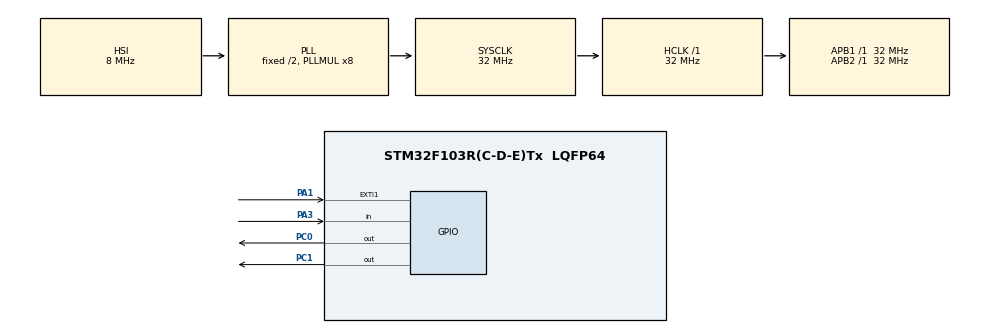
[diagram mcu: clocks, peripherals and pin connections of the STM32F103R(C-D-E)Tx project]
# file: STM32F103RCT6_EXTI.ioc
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Mcu.Family=STM32F1
PA3.GPIO_PuPd=GPIO_PULLUP
NVIC.TIM1_UP_IRQn=true\:0\:0\:false\:false\:true\:true\:true
PC0.Signal=GPIO_Output
RCC.SYSCLKSource=RCC_SYSCLKSOURCE_PLLCLK
ProjectManager.StackSize=0x400
PA13.Signal=SYS_JTMS-SWDIO
NVIC.EXTI1_IRQn=true\:0\:0\:false\:false\:true\:true\:true
TIM1.Prescaler=9
ProjectManager.TargetToolchain=STM32CubeIDE
RCC.HCLKFreq_Value=32000000
RCC.APB2TimFreq_Value=32000000
RCC.USBFreq_Value=32000000
PA1.GPIO_PuPd=GPIO_PULLUP
PA1.Signal=GPXTI1
RCC.AHBFreq_Value=32000000
board=custom
RCC.PLLMUL=RCC_PLL_MUL8
RCC.APB2Freq_Value=32000000
PA14.Mode=Serial_Wire
PA13.Mode=Serial_Wire
Mcu.Name=STM32F103R(C-D-E)Tx
VP_TIM1_VS_ClockSourceINT.Mode=Internal
RCC.SYSCLKFreq_VALUE=32000000
Mcu.Package=LQFP64
PA14.Signal=SYS_JTCK-SWCLK
ProjectManager.HeapSize=0x200
NVIC.PriorityGroup=NVIC_PRIORITYGROUP_4
RCC.APB1TimFreq_Value=32000000
TIM1.Period=319
RCC.APB1Freq_Value=32000000
PA1.GPIO_ModeDefaultEXTI=GPIO_MODE_IT_RISING_FALLING
PC1.Signal=GPIO_Output
PA3.Signal=GPIO_Input

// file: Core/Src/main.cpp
/* USER CODE BEGIN Header */
/**
  ******************************************************************************
  * @file           : main.c
  * @brief          : Main program body
  ******************************************************************************
  * @attention
  *
  * <h2><center>&copy; Copyright (c) 2021 STMicroelectronics.
  * All rights reserved.</center></h2>
  *
  * This software component is licensed by ST under BSD 3-Clause license,
  * the "License"; You may not use this file except in compliance with the
  * License. You may obtain a copy of the License at:
  *                        opensource.org/licenses/BSD-3-Clause
  *
  ******************************************************************************
  */
/* USER CODE END Header */
#include "main.h"
#include <STM32Flash.h>
#include <RCSwitch.h>
#include "stm32f1xx_hal.h"

#define DATA_START_ADDRESS	((uint32_t)0x0801FC00)

TIM_HandleTypeDef htim1;
void SystemClock_Config(void);
static void MX_GPIO_Init(void);
static void MX_TIM1_Init(void);

RCSwitch mySwitch = RCSwitch();
STM32Flash flash;
/***********************************************************/
void UpdateRemoteCode(void)
{
	uint32_t temp=0, varNew = 0;
	uint32_t buff[4];
	for(uint8_t i=0; i<4; i++)
	{
		temp = i;
		while(!mySwitch.available());
		varNew = (uint32_t)mySwitch.getReceivedValue();
		if(i==0)
		{
			buff[i] = varNew;
		}
		else
		{
			if(buff[i-1] != varNew)
			{
				buff[i] = varNew;
			}
			else
			{
				i= temp -1;
			}
		}
		mySwitch.resetAvailable();
	}
	flash.flashErase(DATA_START_ADDRESS);
	for(uint8_t i=0; i<4; i++)
	{
		HAL_FLASH_Program(FLASH_TYPEPROGRAM_WORD, DATA_START_ADDRESS+ i*4, buff[i]);
	}
}
/***********************************************************/
uint8_t GetPosition(uint32_t data)
{
	for(uint32_t i=0; i<4; i++)
	{
		if( (*(uint32_t*)(DATA_START_ADDRESS + i*4)) == data)
		{
			return i;
		}
	}
	return 4;
}
/***********************************************************/
int main(void)
{

	uint32_t blink_count = 0;
	HAL_Init();
	SystemClock_Config();
	MX_GPIO_Init();
	MX_TIM1_Init();
	HAL_TIM_Base_Start_IT(&htim1);
	mySwitch.enableReceive(0);
	Utility().delayInit();
	if(HAL_GPIO_ReadPin(GPIOA, GPIO_PIN_3)== GPIO_PIN_RESET)
	{
		UpdateRemoteCode();
	}
	while (1)
	{
		if (mySwitch.available())
		{
			switch (GetPosition((uint32_t)mySwitch.getReceivedValue()))
			{
			case 0:
				HAL_GPIO_WritePin(GPIOC, GPIO_PIN_0, GPIO_PIN_SET);
				break;
			case 1:
				HAL_GPIO_WritePin(GPIOC, GPIO_PIN_0, GPIO_PIN_RESET);
				break;
			case 2:
				HAL_GPIO_WritePin(GPIOC, GPIO_PIN_1, GPIO_PIN_SET);
				break;
			case 3:
				HAL_GPIO_WritePin(GPIOC, GPIO_PIN_1, GPIO_PIN_RESET);
				break;
			}
			mySwitch.resetAvailable();
			HAL_GPIO_TogglePin(GPIOC, GPIO_PIN_1);
		}
		blink_count++;
		if(blink_count>0xDFFFF)
		{
			//HAL_GPIO_TogglePin(GPIOC, GPIO_PIN_1);
			blink_count = 0;
		}
	}
}
/***********************************************************/
void HAL_GPIO_EXTI_Callback(uint16_t GPIO_Pin)
{
	if(GPIO_Pin==GPIO_PIN_1)
	{
		mySwitch.handleInterrupt();
	}
}
/***********************************************************/
void SystemClock_Config(void)
{
  RCC_OscInitTypeDef RCC_OscInitStruct = {0};
  RCC_ClkInitTypeDef RCC_ClkInitStruct = {0};

  /** Initializes the RCC Oscillators according to the specified parameters
  * in the RCC_OscInitTypeDef structure.
  */
  RCC_OscInitStruct.OscillatorType = RCC_OSCILLATORTYPE_HSI;
  RCC_OscInitStruct.HSIState = RCC_HSI_ON;
  RCC_OscInitStruct.HSICalibrationValue = RCC_HSICALIBRATION_DEFAULT;
  RCC_OscInitStruct.PLL.PLLState = RCC_PLL_ON;
  RCC_OscInitStruct.PLL.PLLSource = RCC_PLLSOURCE_HSI_DIV2;
  RCC_OscInitStruct.PLL.PLLMUL = RCC_PLL_MUL8;
  if (HAL_RCC_OscConfig(&RCC_OscInitStruct) != HAL_OK)
  {
    Error_Handler();
  }
  /** Initializes the CPU, AHB and APB buses clocks
  */
  RCC_ClkInitStruct.ClockType = RCC_CLOCKTYPE_HCLK|RCC_CLOCKTYPE_SYSCLK
                              |RCC_CLOCKTYPE_PCLK1|RCC_CLOCKTYPE_PCLK2;
  RCC_ClkInitStruct.SYSCLKSource = RCC_SYSCLKSOURCE_PLLCLK;
  RCC_ClkInitStruct.AHBCLKDivider = RCC_SYSCLK_DIV1;
  RCC_ClkInitStruct.APB1CLKDivider = RCC_HCLK_DIV1;
  RCC_ClkInitStruct.APB2CLKDivider = RCC_HCLK_DIV1;

  if (HAL_RCC_ClockConfig(&RCC_ClkInitStruct, FLASH_LATENCY_1) != HAL_OK)
  {
    Error_Handler();
  }
}

static void MX_TIM1_Init(void)
{

  TIM_ClockConfigTypeDef sClockSourceConfig = {0};
  TIM_MasterConfigTypeDef sMasterConfig = {0};

  htim1.Instance = TIM1;
  htim1.Init.Prescaler = 9;
  htim1.Init.CounterMode = TIM_COUNTERMODE_UP;
  htim1.Init.Period = 319;
  htim1.Init.ClockDivision = TIM_CLOCKDIVISION_DIV1;
  htim1.Init.RepetitionCounter = 0;
  htim1.Init.AutoReloadPreload = TIM_AUTORELOAD_PRELOAD_DISABLE;
  if (HAL_TIM_Base_Init(&htim1) != HAL_OK)
  {
    Error_Handler();
  }
  sClockSourceConfig.ClockSource = TIM_CLOCKSOURCE_INTERNAL;
  if (HAL_TIM_ConfigClockSource(&htim1, &sClockSourceConfig) != HAL_OK)
  {
    Error_Handler();
  }
  sMasterConfig.MasterOutputTrigger = TIM_TRGO_RESET;
  sMasterConfig.MasterSlaveMode = TIM_MASTERSLAVEMODE_DISABLE;
  if (HAL_TIMEx_MasterConfigSynchronization(&htim1, &sMasterConfig) != HAL_OK)
  {
    Error_Handler();
  }
  /* USER CODE BEGIN TIM1_Init 2 */
  HAL_NVIC_SetPriority(TIM1_UP_IRQn, 0, 0);
  HAL_NVIC_EnableIRQ(TIM1_UP_IRQn);
  /* USER CODE END TIM1_Init 2 */
}

static void MX_GPIO_Init(void)
{
  GPIO_InitTypeDef GPIO_InitStruct = {0};

  /* GPIO Ports Clock Enable */
  __HAL_RCC_GPIOC_CLK_ENABLE();
  __HAL_RCC_GPIOA_CLK_ENABLE();

  /*Configure GPIO pin Output Level */
  HAL_GPIO_WritePin(GPIOC, GPIO_PIN_0|GPIO_PIN_1, GPIO_PIN_RESET);

  /*Configure GPIO pins : PC0 PC1 */
  GPIO_InitStruct.Pin = GPIO_PIN_0|GPIO_PIN_1;
  GPIO_InitStruct.Mode = GPIO_MODE_OUTPUT_PP;
  GPIO_InitStruct.Pull = GPIO_NOPULL;
  GPIO_InitStruct.Speed = GPIO_SPEED_FREQ_LOW;
  HAL_GPIO_Init(GPIOC, &GPIO_InitStruct);

  /*Configure GPIO pin : PA1 */
  GPIO_InitStruct.Pin = GPIO_PIN_1;
  GPIO_InitStruct.Mode = GPIO_MODE_IT_RISING_FALLING;
  GPIO_InitStruct.Pull = GPIO_PULLUP;
  HAL_GPIO_Init(GPIOA, &GPIO_InitStruct);

  /*Configure GPIO pin : PA3 */
  GPIO_InitStruct.Pin = GPIO_PIN_3;
  GPIO_InitStruct.Mode = GPIO_MODE_INPUT;
  GPIO_InitStruct.Pull = GPIO_PULLUP;
  HAL_GPIO_Init(GPIOA, &GPIO_InitStruct);

  /* EXTI interrupt init*/
  HAL_NVIC_SetPriority(EXTI1_IRQn, 0, 0);
  HAL_NVIC_EnableIRQ(EXTI1_IRQn);

}

void Error_Handler(void)
{
  __disable_irq();
  while (1)
  {
  }
}

/************************ (C) COPYRIGHT STMicroelectronics *****END OF FILE****/
